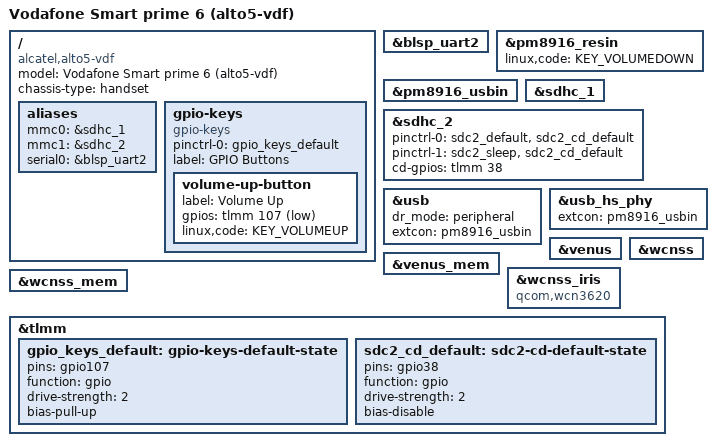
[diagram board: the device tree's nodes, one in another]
// SPDX-License-Identifier: GPL-2.0-only

/dts-v1/;

#include "msm8916-pm8916.dtsi"
#include <dt-bindings/gpio/gpio.h>

/ {
	model = "Vodafone Smart prime 6 (alto5-vdf)";
	compatible = "alcatel,alto5-vdf", "qcom,msm8916";
	chassis-type = "handset";

	aliases {
		mmc0 = &sdhc_1; /* eMMC */
		mmc1 = &sdhc_2; /* SD card */
		serial0 = &blsp_uart2;
	};

	gpio-keys {
		compatible = "gpio-keys";

		pinctrl-0 = <&gpio_keys_default>;
		pinctrl-names = "default";

		label = "GPIO Buttons";

		volume-up-button {
			label = "Volume Up";
			gpios = <&tlmm 107 GPIO_ACTIVE_LOW>;
			linux,code = <KEY_VOLUMEUP>;
		};
	};
};

&blsp_uart2 {
	status = "okay";
};

&pm8916_resin {
	linux,code = <KEY_VOLUMEDOWN>;
	status = "okay";
};

&pm8916_usbin {
	status = "okay";
};

&sdhc_1 {
	status = "okay";
};

&sdhc_2 {
	pinctrl-0 = <&sdc2_default &sdc2_cd_default>;
	pinctrl-1 = <&sdc2_sleep &sdc2_cd_default>;
	pinctrl-names = "default", "sleep";

	cd-gpios = <&tlmm 38 GPIO_ACTIVE_HIGH>;

	status = "okay";
};

&usb {
	dr_mode = "peripheral";
	extcon = <&pm8916_usbin>;
	status = "okay";
};

&usb_hs_phy {
	extcon = <&pm8916_usbin>;
};

&venus {
	status = "okay";
};

&venus_mem {
	status = "okay";
};

&wcnss {
	status = "okay";
};

&wcnss_iris {
	compatible = "qcom,wcn3620";
};

&wcnss_mem {
	status = "okay";
};

&tlmm {
	gpio_keys_default: gpio-keys-default-state {
		pins = "gpio107";
		function = "gpio";
		drive-strength = <2>;
		bias-pull-up;
	};

	sdc2_cd_default: sdc2-cd-default-state {
		pins = "gpio38";
		function = "gpio";
		drive-strength = <2>;
		bias-disable;
	};
};
